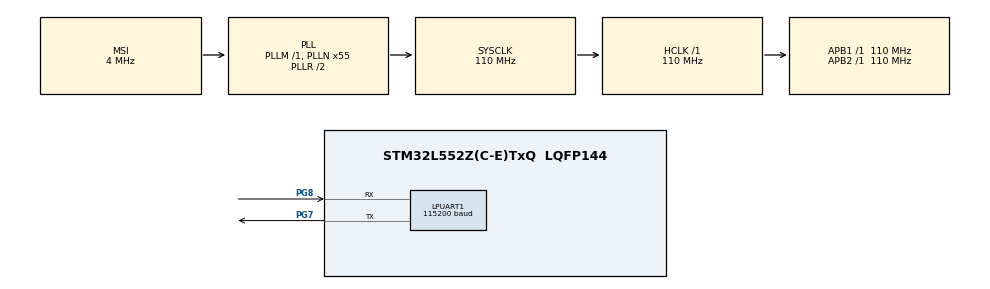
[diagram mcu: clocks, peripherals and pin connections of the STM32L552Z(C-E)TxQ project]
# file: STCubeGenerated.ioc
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LPUART1.BaudRate=115200
Mcu.Family=STM32L5
Mcu.Name=STM32L552Z(C-E)TxQ
Mcu.Package=LQFP144
Mcu.TrustZone=disable
NVIC.PriorityGroup=NVIC_PRIORITYGROUP_3
PG7.GPIO_Speed=GPIO_SPEED_FREQ_VERY_HIGH
PG7.Mode=Asynchronous
PG7.Signal=LPUART1_TX
PG8.GPIO_Speed=GPIO_SPEED_FREQ_VERY_HIGH
PG8.Mode=Asynchronous
PG8.Signal=LPUART1_RX
ProjectManager.HeapSize=0x200
ProjectManager.StackSize=0x400
ProjectManager.TargetToolchain=MDK-ARM V5.27
RCC.ADCFreq_Value=16000000
RCC.AHBFreq_Value=110000000
RCC.APB1Freq_Value=110000000
RCC.APB1TimFreq_Value=110000000
RCC.APB2Freq_Value=110000000
RCC.APB2TimFreq_Value=110000000
RCC.CK48CLockSelection=RCC_USBCLKSOURCE_MSI
RCC.CortexFreq_Value=110000000
RCC.HCLKFreq_Value=110000000
RCC.HSE_VALUE=16000000
RCC.HSI48_VALUE=48000000
RCC.HSI_VALUE=16000000
RCC.LPUART1CLockSelectionVirtual=RCC_LPUART1CLKSOURCE_HSI
RCC.LSE_VALUE=32768
RCC.MSI_VALUE=4000000
RCC.PLLN=55
RCC.SYSCLKFreq_VALUE=110000000
RCC.SYSCLKSource=RCC_SYSCLKSOURCE_PLLCLK
RCC.USBFreq_Value=4000000
RCC.VCOOutputFreq_Value=220000000
VP_HASH_VS_HASH.Mode=HASH_Activate
VP_ICACHE_VS_ICACHE.Mode=DefaultMode
VP_PWR_VS_DBSignals.Mode=DisableDeadBatterySignals
VP_RNG_VS_RNG.Mode=RNG_Activate
board=custom

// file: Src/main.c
/* USER CODE BEGIN Header */
/**
  ******************************************************************************
  * @file           : main.c
  * @brief          : Main program body
  ******************************************************************************
  * @attention
  *
  * <h2><center>&copy; Copyright (c) 2020 STMicroelectronics.
  * All rights reserved.</center></h2>
  *
  * This software component is licensed by ST under BSD 3-Clause license,
  * the "License"; You may not use this file except in compliance with the
  * License. You may obtain a copy of the License at:
  *                        opensource.org/licenses/BSD-3-Clause
  *
  ******************************************************************************
  */
/* USER CODE END Header */
#include "main.h"

/* USER CODE BEGIN Includes */
#include "tfm_hal_platform.h"
/* USER CODE END Includes */

/* USER CODE BEGIN PD */
#define main main0
/* USER CODE END PD */

UART_HandleTypeDef hlpuart1;

void SystemClock_Config(void);
static void MX_GPIO_Init(void);
static void MX_ICACHE_Init(void);
static void MX_LPUART1_UART_Init(void);

int main(void)
{

  /* MCU Configuration--------------------------------------------------------*/

  /* Reset of all peripherals, Initializes the Flash interface and the Systick. */
  HAL_Init();

  /* Configure the system clock */
  SystemClock_Config();

  /* Initialize all configured peripherals */
  MX_GPIO_Init();
  MX_ICACHE_Init();
  MX_LPUART1_UART_Init();

  /* Infinite loop */
  /* USER CODE BEGIN WHILE */
//  while (1)
//  {
    /* USER CODE END WHILE */

    /* USER CODE BEGIN 3 */
//  }
  return 0;
  /* USER CODE END 3 */
}

void SystemClock_Config(void)
{
  RCC_OscInitTypeDef RCC_OscInitStruct = {0};
  RCC_ClkInitTypeDef RCC_ClkInitStruct = {0};

  /** Configure the main internal regulator output voltage
  */
  if (HAL_PWREx_ControlVoltageScaling(PWR_REGULATOR_VOLTAGE_SCALE0) != HAL_OK)
  {
    Error_Handler();
  }
  /** Initializes the RCC Oscillators according to the specified parameters
  * in the RCC_OscInitTypeDef structure.
  */
  RCC_OscInitStruct.OscillatorType = RCC_OSCILLATORTYPE_HSI|RCC_OSCILLATORTYPE_MSI;
  RCC_OscInitStruct.HSIState = RCC_HSI_ON;
  RCC_OscInitStruct.HSICalibrationValue = RCC_HSICALIBRATION_DEFAULT;
  RCC_OscInitStruct.MSIState = RCC_MSI_ON;
  RCC_OscInitStruct.MSICalibrationValue = RCC_MSICALIBRATION_DEFAULT;
  RCC_OscInitStruct.MSIClockRange = RCC_MSIRANGE_6;
  RCC_OscInitStruct.PLL.PLLState = RCC_PLL_ON;
  RCC_OscInitStruct.PLL.PLLSource = RCC_PLLSOURCE_MSI;
  RCC_OscInitStruct.PLL.PLLM = 1;
  RCC_OscInitStruct.PLL.PLLN = 55;
  RCC_OscInitStruct.PLL.PLLP = RCC_PLLP_DIV7;
  RCC_OscInitStruct.PLL.PLLQ = RCC_PLLQ_DIV2;
  RCC_OscInitStruct.PLL.PLLR = RCC_PLLR_DIV2;
  if (HAL_RCC_OscConfig(&RCC_OscInitStruct) != HAL_OK)
  {
    Error_Handler();
  }
  /** Initializes the CPU, AHB and APB buses clocks
  */
  RCC_ClkInitStruct.ClockType = RCC_CLOCKTYPE_HCLK|RCC_CLOCKTYPE_SYSCLK
                              |RCC_CLOCKTYPE_PCLK1|RCC_CLOCKTYPE_PCLK2;
  RCC_ClkInitStruct.SYSCLKSource = RCC_SYSCLKSOURCE_PLLCLK;
  RCC_ClkInitStruct.AHBCLKDivider = RCC_SYSCLK_DIV1;
  RCC_ClkInitStruct.APB1CLKDivider = RCC_HCLK_DIV1;
  RCC_ClkInitStruct.APB2CLKDivider = RCC_HCLK_DIV1;

  if (HAL_RCC_ClockConfig(&RCC_ClkInitStruct, FLASH_LATENCY_5) != HAL_OK)
  {
    Error_Handler();
  }
}

static void MX_ICACHE_Init(void)
{

  /** Enable instruction cache (default 2-ways set associative cache)
  */
  if (HAL_ICACHE_Enable() != HAL_OK)
  {
    Error_Handler();
  }

}

static void MX_LPUART1_UART_Init(void)
{

  hlpuart1.Instance = LPUART1;
  hlpuart1.Init.BaudRate = 115200;
  hlpuart1.Init.WordLength = UART_WORDLENGTH_8B;
  hlpuart1.Init.StopBits = UART_STOPBITS_1;
  hlpuart1.Init.Parity = UART_PARITY_NONE;
  hlpuart1.Init.Mode = UART_MODE_TX_RX;
  hlpuart1.Init.HwFlowCtl = UART_HWCONTROL_NONE;
  hlpuart1.Init.OneBitSampling = UART_ONE_BIT_SAMPLE_DISABLE;
  hlpuart1.Init.ClockPrescaler = UART_PRESCALER_DIV1;
  hlpuart1.AdvancedInit.AdvFeatureInit = UART_ADVFEATURE_NO_INIT;
  hlpuart1.FifoMode = UART_FIFOMODE_DISABLE;
  if (HAL_UART_Init(&hlpuart1) != HAL_OK)
  {
    Error_Handler();
  }
  if (HAL_UARTEx_SetTxFifoThreshold(&hlpuart1, UART_TXFIFO_THRESHOLD_1_8) != HAL_OK)
  {
    Error_Handler();
  }
  if (HAL_UARTEx_SetRxFifoThreshold(&hlpuart1, UART_RXFIFO_THRESHOLD_1_8) != HAL_OK)
  {
    Error_Handler();
  }
  if (HAL_UARTEx_DisableFifoMode(&hlpuart1) != HAL_OK)
  {
    Error_Handler();
  }

}

static void MX_GPIO_Init(void)
{

  /* GPIO Ports Clock Enable */
  __HAL_RCC_GPIOG_CLK_ENABLE();
  HAL_PWREx_EnableVddIO2();

}

/* USER CODE BEGIN 4 */
/* Platform specific initialization */
enum tfm_hal_status_t tfm_hal_platform_init(void)
{
  __enable_irq();
  main();
  return TFM_HAL_SUCCESS;
}
/* USER CODE END 4 */

void Error_Handler(void)
{
}

/************************ (C) COPYRIGHT STMicroelectronics *****END OF FILE****/
